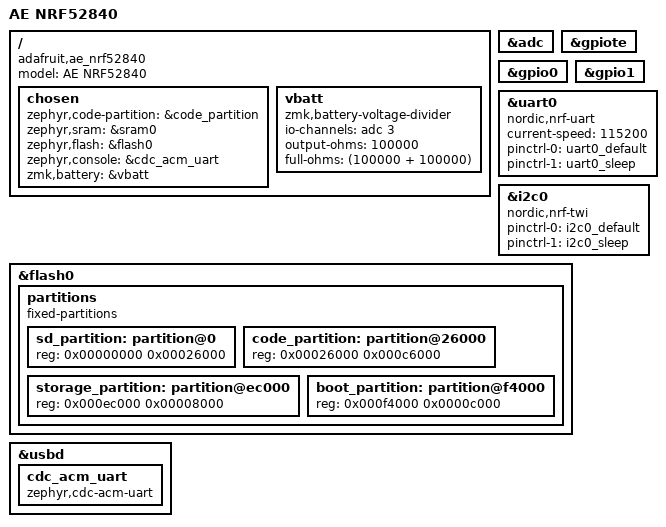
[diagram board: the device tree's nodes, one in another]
/*
 * Copyright (c) 2021 The ZMK Contributors
 *
 * SPDX-License-Identifier: MIT
 */

/dts-v1/;
#include <nordic/nrf52840_qiaa.dtsi>
#include "ae_nrf52840-pinctrl.dtsi"
#include "ae_nrf52840.dtsi"

/ {

	model = "AE NRF52840";
	compatible = "adafruit,ae_nrf52840";

	chosen {
		zephyr,code-partition = &code_partition;
		zephyr,sram = &sram0;
		zephyr,flash = &flash0;
		zephyr,console = &cdc_acm_uart;
		zmk,battery = &vbatt;
	};

	/* 
	arduino_adc: analog-connector {
		compatible = "arduino,uno-adc";
		#io-channel-cells = <1>;
		io-channel-map = <0 &adc 1>,	
						 <1 &adc 2>,	
						 <2 &adc 4>,	
						 <3 &adc 5>,	
						 <4 &adc 6>,	
						 <5 &adc 7>;	
	};
	*/

	vbatt: vbatt {
		compatible = "zmk,battery-voltage-divider";
		io-channels = <&adc 3>;
		output-ohms = <100000>;
		full-ohms = <(100000 + 100000)>;
	};
};

&adc {
	status = "okay";
};

&gpiote {
	status = "okay";
};

&gpio0 {
	status = "okay";
};

&gpio1 {
	status = "okay";
};

&uart0 {
	compatible = "nordic,nrf-uart";
	current-speed = <115200>;
	pinctrl-0 = <&uart0_default>;
    pinctrl-1 = <&uart0_sleep>;
	pinctrl-names = "default", "sleep";
};

&i2c0 {
	compatible = "nordic,nrf-twi";
	pinctrl-0 = <&i2c0_default>;
    pinctrl-1 = <&i2c0_sleep>;
	pinctrl-names = "default", "sleep";
};

/*
&spi1 {
	compatible = "nordic,nrf-spi";
	status = "okay";
	sck-pin = <14>;
	mosi-pin = <13>;
	miso-pin = <15>;
};

&qspi {
	status = "okay";
	sck-pin = <19>;
	io-pins = <17>, <22>, <23>, <21>;
	csn-pins = <20>;
	gd25q16: gd25q16@0 {
		compatible = "nordic,qspi-nor";
		reg = <0>;
		writeoc = "pp4io";
		readoc = "read4io";
		sck-frequency = <16000000>;
		label = "GD25Q16";
		jedec-id = [c8 40 15];
		size = <16777216>;
		has-dpd;
		t-enter-dpd = <20000>;
		t-exit-dpd = <20000>;
	};
};
 */

&flash0 {
	/*
	* For more information, see:
	* https://docs.zephyrproject.org/latest/guides/dts/legacy-macros.html#legacy-flash-partitions
	*/
	partitions {
		compatible = "fixed-partitions";
		#address-cells = <1>;
		#size-cells = <1>;

		sd_partition: partition@0 {
			reg = <0x00000000 0x00026000>;
		};
		code_partition: partition@26000 {
			reg = <0x00026000 0x000c6000>;
		};

		/*
			* The flash starting at 0x000ec000 and ending at
			* 0x000f3fff is reserved for use by the application.
			*/

		/*
			* Storage partition will be used by FCB/LittleFS/NVS
			* if enabled.
			*/
		storage_partition: partition@ec000 {
			reg = <0x000ec000 0x00008000>;
		};

		boot_partition: partition@f4000 {
			reg = <0x000f4000 0x0000c000>;
		};
	};
};

&usbd {
	/*compatible = "nordic,nrf-usbd";*/
	status = "okay";
	cdc_acm_uart: cdc_acm_uart {
		compatible = "zephyr,cdc-acm-uart";
	};
};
